# ESP32S31_RADIO register map
Vendor: Espressif; Series: ESP32-S31; File version: 3.52
Registers are 32-bit, read-write, no defined reset value unless marked. A register's access mark holds for its fields unless they carry their own. Offsets are from the block's base; [hi:lo] are bit positions; 'fields as' and 'values as' point back to an identical list.

## BTDM_RUNTIME_CONTROL — Sparse BTDM low-level runtime and sleep-control window. Complete ESP32-S31 functions prove only the recorded access directions, finite images, low-24-bit publications and four isolated RMW controls. The independently role-mapped runtime-timer start command is named; all other positional names deliberately avoid assigning undocumented peripheral semantics.
Base 0x2010D000
0x00 RUNTIME_TIMER_START_COMMAND wo — Project-assigned name. Complete current leaf writes finite image 1; an instruction-identical public same-chip predecessor identifies the operation as r_btdm_hal_rtc_start.
  [31:0] COMMAND — Project-assigned name. Complete command image that starts the BTDM runtime timer.
    on write: 1=START (Start the runtime timer during controller hardware enable.)
0x04 WORD_0004_OPAQUE wo — Opaque: meaning not established. Complete runtime functions write the finite image 1.
0x08 WORD_0008_OPAQUE wo — Opaque: meaning not established. Complete initialization writes the finite image 1.
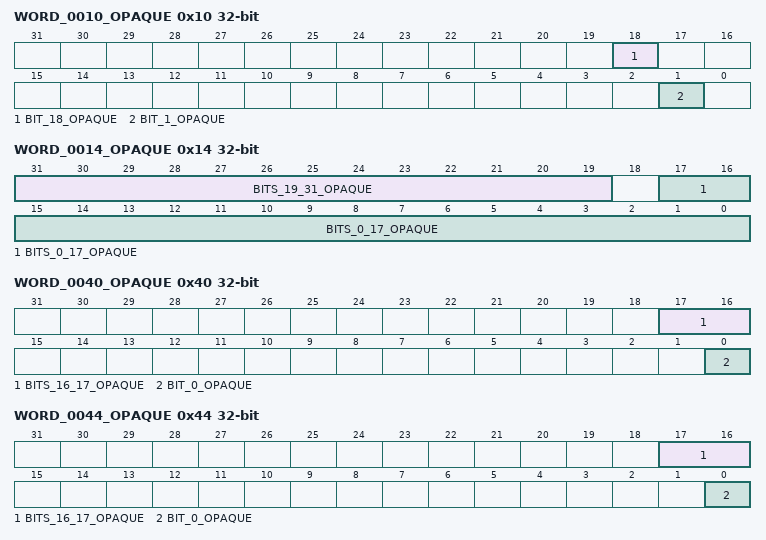
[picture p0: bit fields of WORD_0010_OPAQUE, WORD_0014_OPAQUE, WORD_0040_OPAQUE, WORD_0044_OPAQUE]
0x10 WORD_0010_OPAQUE wo — Opaque: meaning not established. Complete runtime functions write the independently observed finite images 2 and 0x00040000.
  [18] BIT_18_OPAQUE — Opaque: meaning not established. Observed source use; the individual hardware meaning is unknown.
  [1] BIT_1_OPAQUE — Opaque: meaning not established. Observed source use; the individual hardware meaning is unknown.
0x14 WORD_0014_OPAQUE wo — Opaque: meaning not established. Complete runtime functions write the independently observed finite images 0xFFFFFFFF and 0x00040000.
  [31:19] BITS_19_31_OPAQUE — Opaque: meaning not established. Observed source use; the individual hardware meaning is unknown.
  [17:0] BITS_0_17_OPAQUE — Opaque: meaning not established. Observed source use; the individual hardware meaning is unknown.
0x1C WORD_001C_OPAQUE — Opaque: meaning not established. One complete runtime function reads the complete word and writes the finite zero image. Inner state encoding remains unknown.
  [7:0] BITS_0_7_OPAQUE — Opaque: meaning not established. Observed source use; the individual hardware meaning is unknown.
0x20 WORD_0020_OPAQUE — Opaque: meaning not established. Complete state word read by runtime functions and cleared by two complete paths.
  fields as WORD_001C_OPAQUE
0x24 WORD_0024_OPAQUE — Opaque: meaning not established. State word whose low byte is sampled independently; complete writes publish the finite images zero and one.
  [7:0] LOW_BYTE — Project-assigned name.
0x2C WORD_002C_OPAQUE — Opaque: meaning not established. State word whose low byte is sampled independently; complete runtime paths clear the word.
  [7:0] LOW_BYTE — Project-assigned name.
0x34 WORD_0034_OPAQUE wo — Opaque: meaning not established. Complete initialization writes the finite image 0xFFFFFFFF.
0x38 WORD_0038_OPAQUE ro — Opaque: meaning not established. Complete word read by a runtime status path.
  [31:0] BITS_0_31_OPAQUE — Opaque: meaning not established.
0x40 WORD_0040_OPAQUE wo — Opaque: meaning not established. Complete runtime functions write finite images with independently observed bits 0, 16 and 17.
  [17:16] BITS_16_17_OPAQUE — Opaque: meaning not established. Observed source use; the individual hardware meaning is unknown.
  [0] BIT_0_OPAQUE — Opaque: meaning not established. Observed source use; the individual hardware meaning is unknown.
0x44 WORD_0044_OPAQUE wo — Opaque: meaning not established. Complete runtime functions write finite images with independently observed bits 0, 16 and 17.
  fields as WORD_0040_OPAQUE
0x48 WORD_0048_OPAQUE ro — Opaque: meaning not established. Complete word read by multiple runtime functions.
  [31:0] BITS_0_31_OPAQUE — Opaque: meaning not established.
0x4C WORD_004C_OPAQUE wo — Opaque: meaning not established. Complete initialization writes the finite zero image.
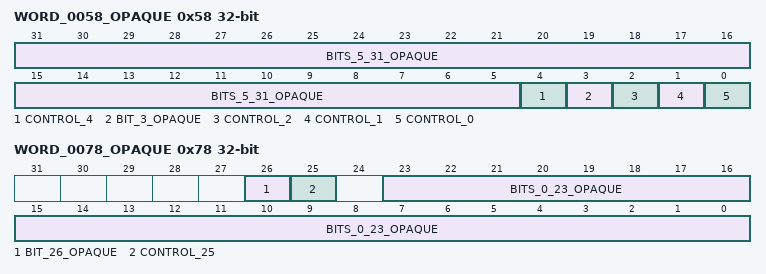
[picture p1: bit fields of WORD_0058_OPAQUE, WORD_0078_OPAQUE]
0x58 WORD_0058_OPAQUE — Opaque: meaning not established. Shared runtime control word with independently observed RMW operations over bits 0, 1, 2 and 4. Other bits are preserved.
  [31:5] BITS_5_31_OPAQUE — Opaque: meaning not established. Observed source use; the individual hardware meaning is unknown.
  [4] CONTROL_4 — Project-assigned name.
  [3] BIT_3_OPAQUE — Opaque: meaning not established. Observed source use; the individual hardware meaning is unknown.
  [2] CONTROL_2 ro — Project-assigned name.
  [1] CONTROL_1 — Project-assigned name.
  [0] CONTROL_0 — Project-assigned name.
0x64 WORD_0064_OPAQUE — Opaque: meaning not established. One complete runtime function reads the complete word and publishes complete dynamic images. The image remains a register-level fact.
  [23:0] BITS_0_23_OPAQUE — Opaque: meaning not established. Observed source use; the individual hardware meaning is unknown.
0x68 WORD_0068_OPAQUE wo — Opaque: meaning not established. Complete publication replaces bits 0..23 with a runtime-derived value and clears bits 24..31.
  [23:0] BITS_0_23_OPAQUE — Opaque: meaning not established.
0x6C WORD_006C_OPAQUE — Opaque: meaning not established. Complete word is read by one runtime path and receives either a complete runtime-derived image or a runtime-derived low-24-bit image.
  [31:0] BITS_0_31_OPAQUE — Opaque: meaning not established.
0x78 WORD_0078_OPAQUE — Opaque: meaning not established. Initialization sets bit 25 through a fresh-read RMW. Other bits are preserved.
  [26] BIT_26_OPAQUE — Opaque: meaning not established. Observed source use; the individual hardware meaning is unknown.
  [25] CONTROL_25 — Project-assigned name.
  [23:0] BITS_0_23_OPAQUE — Opaque: meaning not established. Observed source use; the individual hardware meaning is unknown.
